# STM32G564 register map
File version: 2.0.0
CPU: CM33 r0p4, little endian, MPU, FPU, 4 interrupt priority bits
Registers are 32-bit, read-write, reset 0x0 unless marked. A register's access mark holds for its fields unless they carry their own. Offsets are from the block's base; [hi:lo] are bit positions; {n}, {i} and the like mark numbered series; 'fields as' and 'values as' point back to an identical list.

## TIM15 — TIM15 address block description
Base 0x40014000
Same registers: TIM15_S 0x50014000
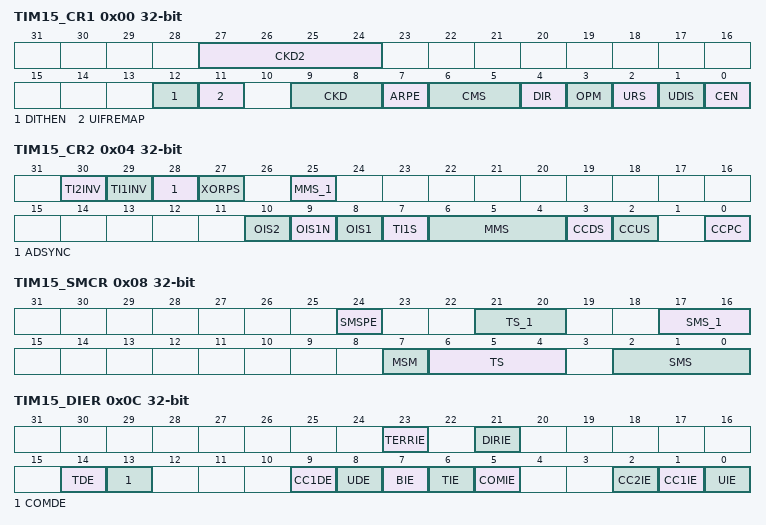
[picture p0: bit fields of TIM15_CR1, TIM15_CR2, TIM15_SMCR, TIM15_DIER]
0x00 TIM15_CR1 — TIM15 control register 1
  [27:24] CKD2 — Clock division 2
    0=No Division; 1=tless thansub>DTS2less than/sub> = 4*tless thansub>DTSless than/sub>; 2=tless thansub>DTS2less than/sub> = 16*tless thansub>DTSless than/sub>; 3=tless thansub>DTS2less than/sub> = 64*tless thansub>DTSless than/sub>; 4=tless thansub>DTS2less than/sub> = 256*tless thansub>DTSless than/sub>; 5=tless thansub>DTS2less than/sub> = 1024*tless thansub>DTSless than/sub>; 6=tless thansub>DTS2less than/sub> = 4096*tless thansub>DTSless than/sub>; 7=tless thansub>DTS2less than/sub> = 16384*tless thansub>DTSless than/sub>; 8=tless thansub>DTS2less than/sub> = 65536*tless thansub>DTSless than/sub>; 9=tless thansub>DTS2less than/sub> = 262144*tless thansub>DTSless than/sub>
  [12] DITHEN — Dithering enable
    0=Dithering disabled; 1=Dithering enabled
  [11] UIFREMAP — UIF status bit remapping
    0=No remapping. UIF status bit is not copied to TIM15_CNT register bit 31.; 1=Remapping enabled. UIF status bit is copied to TIM15_CNT register bit 31.
  [9:8] CKD — Clock division
    0=tless thansub>DTS less than/sub>= tless thansub>tim_ker_ckless than/sub>; 1=tless thansub>DTSless than/sub> = 2*tless thansub>tim_ker_ckless than/sub>; 2=tless thansub>DTSless than/sub> = 4*tless thansub>tim_ker_ckless than/sub>; 3=tless thansub>DTSless than/sub> = 8*tless thansub>tim_ker_ckless than/sub>
  [7] ARPE — Auto-reload preload enable
    0=TIM15_ARR register is not buffered; 1=TIM15_ARR register is buffered
  [6:5] CMS — Center-aligned mode selection
    0=Edge-aligned mode. The counter counts up or down depending on the direction bit (DIR).; 1=Center-aligned mode 1. The counter counts up and down alternatively. Output compare interrupt flags of channels configured in output (CCxS = 00 in TIMx_CCMRx register) are set only when the counter is counting down.; 2=Center-aligned mode 2. The counter counts up and down alternatively. Output compare interrupt flags of channels configured in output (CCxS = 00 in TIMx_CCMRx register) are set only when the counter is counting up.; 3=Center-aligned mode 3. The counter counts up and down alternatively. Output compare interrupt flags of channels configured in output (CCxS = 00 in TIMx_CCMRx register) are set both when the counter is counting up or down.
  [4] DIR — Direction
    0=Counter used as upcounter; 1=Counter used as downcounter
  [3] OPM — One-pulse mode
    0=Counter is not stopped at update event; 1=Counter stops counting at the next update event (clearing the bit CEN)
  [2] URS — Update request source
    0=Any of the following events generate an update interrupt if enabled. These events can be:; 1=Only counter overflow/underflow generates an update interrupt if enabled
  [1] UDIS — Update disable
    0=UEV enabled. The Update (UEV) event is generated by one of the following events:; 1=UEV disabled. The Update event is not generated, shadow registers keep their value (ARR, PSC, CCRx). However the counter and the prescaler are reinitialized if the UG bit is set or if a hardware reset is received from the slave mode controller.
  [0] CEN — Counter enable
    0=Counter disabled; 1=Counter enabled
0x04 TIM15_CR2 — TIM15 control register 2
  [30] TI2INV — tim_ti2 signal inversion on XOR gate input
    0=tim_ti2 non-inverted; 1=tim_ti2 inverted
  [29] TI1INV — tim_ti1 signal inversion on XOR gate input
    0=tim_ti1 non-inverted; 1=tim_ti1 inverted
  [28] ADSYNC — ADC synchronization
    0=The timer operates independently from the ADC; 1=The timer operation is synchronized with the ADC clock to provide jitter-free sampling point. This mode can be enabled only with specific ADC / timer clock relationship. Refer to Section223.4.36 for requirements.
  [27] XORPS — XOR gate position selection
    0=XOR gate placed before TI1 filter; 1=XOR gate placed after TI1 and TI2 filters
  [25] MMS_1 — MMS[3]
  [10] OIS2 — Output idle state 2 (tim_oc2 output)
    0=tim_oc2 = 0 when MOE = 0; 1=tim_oc2 = 1 when MOE = 0
  [9] OIS1N — Output Idle state 1 (tim_oc1n output)
    0=tim_oc1n = 0 after a dead-time when MOE = 0; 1=tim_oc1n = 1 after a dead-time when MOE = 0
  [8] OIS1 — Output Idle state 1 (tim_oc1 output)
    0=tim_oc1 = 0 after a dead-time when MOE = 0; 1=tim_oc1 = 1 after a dead-time when MOE = 0
  [7] TI1S — tim_ti1 selection
    0=The tim_ti1_in[15:0] multiplexer output is connected to tim_ti1 input; 1=The tim_ti1_in[15:0] and tim_ti2_in[15:0] multiplexers output are connected to the tim_ti1 input (XOR combination)
  [6:4] MMS — MMS[2:0]: Master mode selection
    0=Reset - the UG bit from the TIM15_EGR register is used as trigger output (tim_trgo). If the reset is generated by the trigger input (slave mode controller configured in reset mode) then the signal on tim_trgo is delayed compared to the actual reset.; 1=Enable - the Counter Enable signal CNT_EN is used as trigger output (tim_trgo). It is useful to start several timers at the same time or to control a window in which a slave timer is enable. The Counter Enable signal is generated by a logic AND between CEN control bit and the trigger input when configured in gated mode. When the Counter Enable signal is controlled by the trigger input, there is a delay on tim_trgo, except if the master/slave mode is selected (see the MSM bit description in TIM15_SMCR register).; 2=Update - The update event is selected as trigger output (tim_trgo). For instance a master timer can then be used as a prescaler for a slave timer.; 3=Compare Pulse - The trigger output send a positive pulse when the CC1IF flag is to be set (even if it was already high), as soon as a capture or a compare match occurred (tim_trgo); 4=Compare - tim_oc1refc signal is used as trigger output (tim_trgo); 5=Compare - tim_oc2refc signal is used as trigger output (tim_trgo)
  [3] CCDS — Capture/compare DMA selection
    0=CCx DMA request sent when CCx event occurs; 1=CCx DMA requests sent when update event occurs
  [2] CCUS — Capture/compare control update selection
    0=When capture/compare control bits are preloaded (CCPC = 1), they are updated by setting the COMG bit only; 1=When capture/compare control bits are preloaded (CCPC = 1), they are updated by setting the COMG bit or when an rising edge occurs on tim_trgi
  [0] CCPC — Capture/compare preloaded control
    0=CCxE, CCxNE and OCxM bits are not preloaded; 1=CCxE, CCxNE and OCxM bits are preloaded, after having been written, they are updated only when a commutation event (COM) occurs (COMG bit set or rising edge detected on tim_trgi, depending on the CCUS bit)
0x08 TIM15_SMCR — TIM15 slave mode control register
  [24] SMSPE — SMS preload enable
    0=SMS[4:0] bit field is not preloaded; 1=SMS[4:0] preload is enabled
  [21:20] TS_1 — TS[4:3]
  [17:16] SMS_1 — SMS[4:3]
  [7] MSM — Master/slave mode
    0=No action; 1=The effect of an event on the trigger input (tim_trgi) is delayed to allow a perfect synchronization between the current timer and its slaves (through tim_trgo). It is useful if the user wants to synchronize several timers on a single external event.
  [6:4] TS — TS[2:0]: Trigger selection
    {v}=Internal Trigger {v} (tim_itr{v}) (v=0..3); 4=tim_ti1 Edge Detector (tim_ti1f_ed); 5=Filtered Timer Input 1 (tim_ti1fp1); 6=Filtered Timer Input 2 (tim_ti2fp2)
  [2:0] SMS — SMS[2:0]: Slave mode selection
    0=Slave mode disabled - if CEN = 1 then the prescaler is clocked directly by the internal clock; 1=Quadrature encoder mode 1, x2 mode- Counter counts up/down on tim_ti1fp1 edge depending on tim_ti2fp2 level; 2=Quadrature encoder mode 2, x2 mode - Counter counts up/down on tim_ti2fp2 edge depending on tim_ti1fp1 level; 3=Quadrature encoder mode 3, x4 mode - Counter counts up/down on both tim_ti1fp1 and tim_ti2fp2 edges depending on the level of the other input; 4=Reset mode - Rising edge of the selected trigger input (tim_trgi) reinitializes the counter and generates an update of the registers; 5=Gated mode - The counter clock is enabled when the trigger input (tim_trgi) is high. The counter stops (but is not reset) as soon as the trigger becomes low. Both start and stop of the counter are controlled.; 6=Trigger mode - The counter starts at a rising edge of the trigger tim_trgi (but it is not reset). Only the start of the counter is controlled.; 7=External Clock mode 1 - Rising edges of the selected trigger (tim_trgi) clock the counter
0x0C TIM15_DIER — TIM15 DMA/interrupt enable register
  [23] TERRIE — Transition error interrupt enable
    0=Transition error interrupt disabled; 1=Transition error interrupt enabled
  [21] DIRIE — Direction change interrupt enable
    0=Direction Change interrupt disabled; 1=Direction Change interrupt enabled
  [14] TDE — Trigger DMA request enable
    0=Trigger DMA request disabled; 1=Trigger DMA request enabled
  [13] COMDE — COM DMA request enable
    0=COM DMA request disabled; 1=COM DMA request enabled
  [9] CC1DE — Capture/Compare 1 DMA request enable
    0=CC1 DMA request disabled; 1=CC1 DMA request enabled
  [8] UDE — Update DMA request enable
    0=Update DMA request disabled; 1=Update DMA request enabled
  [7] BIE — Break interrupt enable
    0=Break interrupt disabled; 1=Break interrupt enabled
  [6] TIE — Trigger interrupt enable
    0=Trigger interrupt disabled; 1=Trigger interrupt enabled
  [5] COMIE — COM interrupt enable
    0=COM interrupt disabled; 1=COM interrupt enabled
  [2] CC2IE — Capture/Compare 2 interrupt enable
    0=CC2 interrupt disabled; 1=CC2 interrupt enabled
  [1] CC1IE — Capture/Compare 1 interrupt enable
    0=CC1 interrupt disabled; 1=CC1 interrupt enabled
  [0] UIE — Update interrupt enable
    0=Update interrupt disabled; 1=Update interrupt enabled
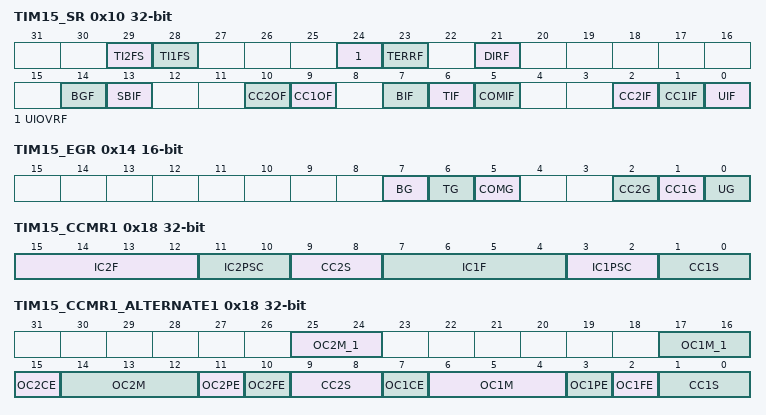
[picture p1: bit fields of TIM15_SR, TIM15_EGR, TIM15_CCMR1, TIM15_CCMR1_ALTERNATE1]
0x10 TIM15_SR — TIM15 status register
  [29] TI2FS ro — tim_ti2f status
    0=tim_ti2f signal is low; 1=tim_ti2f signal is high
  [28] TI1FS ro — tim_ti1f status
    0=tim_ti1f signal is low; 1=tim_ti1f signal is high
  [24] UIOVRF — Update Interrupt Overrun flag
    0=No Update Interrupt Overrun; 1=Update Interrupt Overrun
  [23] TERRF — Transition error interrupt flag
    0=No encoder transition error has been detected; 1=An encoder transition error has been detected
  [21] DIRF — Direction change interrupt flag
    0=No direction change; 1=Direction change
  [14] BGF — Break generation flag
    0=No break event occurred; 1=A break event was forced with the BG bit
  [13] SBIF — System break interrupt flag
    0=No break event occurred; 1=An active level has been detected on the system break input. An interrupt is generated if BIE = 1 in the TIMx_DIER register.
  [10] CC2OF — Capture/Compare 2 overcapture flag
  [9] CC1OF — Capture/Compare 1 overcapture flag
    0=No overcapture has been detected; 1=The counter value has been captured in TIM15_CCR1 register while CC1IF flag was already set
  [7] BIF — Break interrupt flag
    0=No break event occurred; 1=An active level has been detected on the break input
  [6] TIF — Trigger interrupt flag
    0=No trigger event occurred; 1=Trigger interrupt pending
  [5] COMIF — COM interrupt flag
    0=No COM event occurred; 1=COM interrupt pending
  [2] CC2IF — Capture/Compare 2 interrupt flag
  [1] CC1IF — Capture/Compare 1 interrupt flag
    0=No compare match / No input capture occurred; 1=A compare match or an input capture occurred
  [0] UIF — Update interrupt flag
    0=No update occurred; 1=Update interrupt pending. This bit is set by hardware when the registers are updated:
0x14 TIM15_EGR 16-bit — TIM15 event generation register
  [7] BG wo — Break generation
    0=No action; 1=A break event is generated. MOE bit is cleared and BIF flag is set. Related interrupt or DMA transfer can occur if enabled.
  [6] TG wo — Trigger generation
    0=No action; 1=The TIF flag is set in TIM15_SR register. Related interrupt or DMA transfer can occur if enabled
  [5] COMG — Capture/Compare control update generation
    0=No action; 1=When the CCPC bit is set, it is possible to update the CCxE, CCxNE and OCxM bits
  [2] CC2G wo — Capture/Compare 2 generation
  [1] CC1G wo — Capture/Compare 1 generation
    0=No action
  [0] UG wo — Update generation
    0=No action; 1=Reinitialize the counter and generates an update of the registers. Note that the prescaler counter is cleared too (anyway the prescaler ratio is not affected).
0x18 TIM15_CCMR1 — TIM15 capture/compare mode register 1
  [15:12] IC2F — Input capture 2 filter
  [11:10] IC2PSC — Input capture 2 prescaler
  [9:8] CC2S — Capture/Compare 2 selection
    0=CC2 channel is configured as output; 1=CC2 channel is configured as input, tim_ic2 is mapped on tim_ti2; 2=CC2 channel is configured as input, tim_ic2 is mapped on tim_ti1; 3=CC2 channel is configured as input, tim_ic2 is mapped on tim_trc. This mode is working only if an internal trigger input is selected through TS bit (TIM15_SMCR register)
  [7:4] IC1F — Input capture 1 filter
    0=No filter, sampling is done at fless thansub>DTSless than/sub>; 1=fless thansub>SAMPLINGless than/sub> = fless thansub>tim_ker_ckless than/sub>, N = 2; 2=fless thansub>SAMPLINGless than/sub> = fless thansub>tim_ker_ckless than/sub>, N = 4; 3=fless thansub>SAMPLINGless than/sub> = fless thansub>tim_ker_ckless than/sub>, N = 8; 4=fless thansub>SAMPLINGless than/sub> = fless thansub>DTSless than/sub>/2, N = 6; 5=fless thansub>SAMPLINGless than/sub> = fless thansub>DTSless than/sub>/2, N = 8; 6=fless thansub>SAMPLINGless than/sub> = fless thansub>DTSless than/sub>/4, N = 6; 7=fless thansub>SAMPLINGless than/sub> = fless thansub>DTSless than/sub>/4, N = 8; 8=fless thansub>SAMPLINGless than/sub> = fless thansub>DTSless than/sub>/8, N = 6; 9=fless thansub>SAMPLINGless than/sub> = fless thansub>DTSless than/sub>/8, N = 8; 10=fless thansub>SAMPLINGless than/sub> = fless thansub>DTSless than/sub>/16, N = 5; 11=fless thansub>SAMPLINGless than/sub> = fless thansub>DTSless than/sub>/16, N = 6; 12=fless thansub>SAMPLINGless than/sub> = fless thansub>DTSless than/sub>/16, N = 8; 13=fless thansub>SAMPLINGless than/sub> = fless thansub>DTSless than/sub>/32, N = 5; 14=fless thansub>SAMPLINGless than/sub> = fless thansub>DTSless than/sub>/32, N = 6; 15=fless thansub>SAMPLINGless than/sub> = fless thansub>DTSless than/sub>/32, N = 8
  [3:2] IC1PSC — Input capture 1 prescaler
    0=no prescaler, capture is done each time an edge is detected on the capture input; 1=capture is done once every 2 events; 2=capture is done once every 4 events; 3=capture is done once every 8 events
  [1:0] CC1S — Capture/Compare 1 selection
    0=CC1 channel is configured as output; 1=CC1 channel is configured as input, tim_ic1 is mapped on tim_ti1; 2=CC1 channel is configured as input, tim_ic1 is mapped on tim_ti2; 3=CC1 channel is configured as input, tim_ic1 is mapped on tim_trc. This mode is working only if an internal trigger input is selected through TS bit (TIM15_SMCR register)
0x18 TIM15_CCMR1_ALTERNATE1 (alternate view of TIM15_CCMR1) — TIM15 capture/compare mode register 1
  [25:24] OC2M_1 — OC2M[4:3]
  [17:16] OC1M_1 — OC1M[4:3]
  [15] OC2CE — Output compare 2 clear enable
  [14:12] OC2M — OC2M[2:0]: Output compare 2 mode
  [11] OC2PE — Output compare 2 preload enable
  [10] OC2FE — Output compare 2 fast enable
  [9:8] CC2S — Capture/Compare 2 selection
    0=CC2 channel is configured as output; 1=CC2 channel is configured as input, tim_ic2 is mapped on tim_ti2; 2=C2 channel is configured as input, tim_ic2 is mapped on tim_ti1; 3=CC2 channel is configured as input, tim_ic2 is mapped on tim_trc. This mode is working only if an internal trigger input is selected through the TS bit (TIM15_SMCR register)
  [7] OC1CE — Output compare 1 clear enable
    0=tim_oc1ref is not affected by the tim_ocref_clr_int input; 1=tim_oc1ref is cleared as soon as a High level is detected on tim_ocref_clr_int input
  [6:4] OC1M — OC1M[2:0]: Output compare 1 mode
    0=Frozen - The comparison between the output compare register TIM15_CCR1 and the counter TIM15_CNT has no effect on the outputs. This mode can be used when the timer serves as a software timebase. When the frozen mode is enabled during timer operation, the output keeps the state (active or inactive) it had before entering the frozen state.; 1=Set channel 1 to active level on match. tim_oc1ref signal is forced high when the counter TIM15_CNT matches the capture/compare register 1 (TIM15_CCR1).; 2=Set channel 1 to inactive level on match. tim_oc1ref signal is forced low when the counter TIM15_CNT matches the capture/compare register 1 (TIM15_CCR1).; 3=Toggle - tim_oc1ref toggles when TIM15_CNT = TIM15_CCR1; 4=Force inactive level - tim_oc1ref is forced low; 5=Force active level - tim_oc1ref is forced high; 6=PWM mode 1 - Channel 1 is active as long as TIM15_CNTless thanTIM15_CCR1 else inactive; 7=PWM mode 2 - Channel 1 is inactive as long as TIM15_CNTless thanTIM15_CCR1 else active
  [3] OC1PE — Output Compare 1 preload enable
    0=Preload register on TIM15_CCR1 disabled. TIM15_CCR1 can be written at anytime, the new value is taken in account immediately.; 1=Preload register on TIM15_CCR1 enabled. Read/Write operations access the preload register. TIM15_CCR1 preload value is loaded in the active register at each update event.
  [2] OC1FE — Output Compare 1 fast enable
    0=CC1 behaves normally depending on counter and CCR1 values even when the trigger is ON. The minimum delay to activate CC1 output when an edge occurs on the trigger input is 5 clock cycles.; 1=An active edge on the trigger input acts like a compare match on CC1 output. Then, tim_ocx is set to the compare level independently of the result of the comparison. Delay to sample the trigger input and to activate CC1 output is reduced to 3 clock cycles. OCFE acts only if the channel is configured in PWM1 or PWM2 mode.
  [1:0] CC1S — Capture/Compare 1 selection
    values as TIM15_CCMR1.CC1S
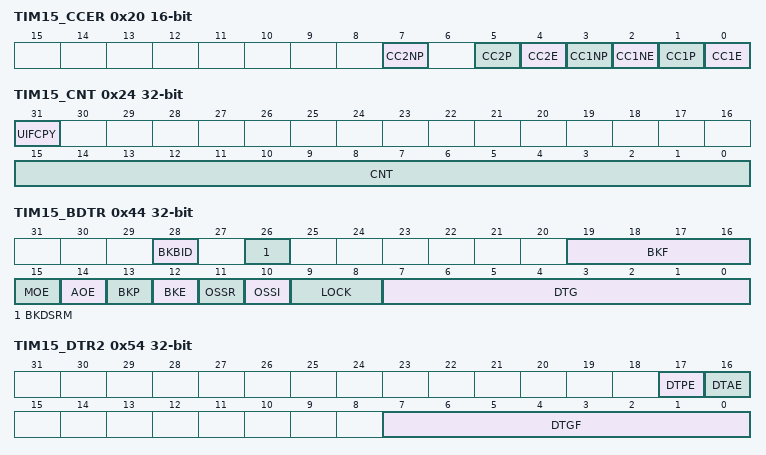
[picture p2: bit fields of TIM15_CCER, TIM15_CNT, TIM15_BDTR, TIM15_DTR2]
0x20 TIM15_CCER 16-bit — TIM15 capture/compare enable register
  [7] CC2NP — Capture/Compare 2 complementary output polarity
  [5] CC2P — Capture/Compare 2 output polarity
  [4] CC2E — Capture/Compare 2 output enable
  [3] CC1NP — Capture/Compare 1 complementary output polarity
    0=tim_oc1n active high; 1=tim_oc1n active low
  [2] CC1NE — Capture/Compare 1 complementary output enable
    0=Off - tim_oc1n is not active. tim_oc1n level is then function of MOE, OSSI, OSSR, OIS1, OIS1N and CC1E bits.; 1=On - tim_oc1n signal is output on the corresponding output pin depending on MOE, OSSI, OSSR, OIS1, OIS1N and CC1E bits
  [1] CC1P — Capture/Compare 1 output polarity
    0=OC1 active high (output mode) / Edge sensitivity selection (input mode, see below); 1=OC1 active low (output mode) / Edge sensitivity selection (input mode, see below)
  [0] CC1E — Capture/Compare 1 output enable
    0=Capture mode disabled / OC1 is not active (see below); 1=Capture mode enabled / OC1 signal is output on the corresponding output pin
0x24 TIM15_CNT — TIM15 counter
  [31] UIFCPY ro — UIF Copy
  [15:0] CNT — Counter value
0x28 TIM15_PSC 16-bit — TIM15 prescaler
  [15:0] PSC — Prescaler value
0x2C TIM15_ARR reset 0xFFFF — TIM15 autoreload register
  [19:0] ARR — Auto-reload value
0x30 TIM15_RCR 16-bit — TIM15 repetition counter register
  [7:0] REP — Repetition counter reload value
0x34 TIM15_CCR1 — TIM15 capture/compare register 1
  [19:0] CCR1 — Capture/compare 1 value
0x38 TIM15_CCR2 — TIM15 capture/compare register 2
  [19:0] CCR2 — Capture/compare 2 value
0x44 TIM15_BDTR — TIM15 break and dead-time register
  [28] BKBID — Break bidirectional
    0=Break input tim_brk in input mode; 1=Break input tim_brk in bidirectional mode
  [26] BKDSRM — Break disarm
    0=Break input tim_brk is armed; 1=Break input tim_brk is disarmed
  [19:16] BKF — Break filter
    0=No filter, tim_brk acts asynchronously; 1=fless thansub>SAMPLINGless than/sub> = fless thansub>tim_ker_ckless than/sub>, N = 2; 2=fless thansub>SAMPLINGless than/sub> = fless thansub>tim_ker_ckless than/sub>, N = 4; 3=fless thansub>SAMPLINGless than/sub> = fless thansub>tim_ker_ckless than/sub>, N = 8; 4=fless thansub>SAMPLINGless than/sub> = fless thansub>DTSless than/sub>/2, N = 6; 5=fless thansub>SAMPLINGless than/sub> = fless thansub>DTSless than/sub>/2, N = 8; 6=fless thansub>SAMPLINGless than/sub> = fless thansub>DTSless than/sub>/4, N = 6; 7=fless thansub>SAMPLINGless than/sub> = fless thansub>DTSless than/sub>/4, N = 8; 8=fless thansub>SAMPLINGless than/sub> = fless thansub>DTSless than/sub>/8, N = 6; 9=fless thansub>SAMPLINGless than/sub> = fless thansub>DTSless than/sub>/8, N = 8; 10=fless thansub>SAMPLINGless than/sub> = fless thansub>DTSless than/sub>/16, N = 5; 11=fless thansub>SAMPLINGless than/sub> = fless thansub>DTSless than/sub>/16, N = 6; 12=fless thansub>SAMPLINGless than/sub> = fless thansub>DTSless than/sub>/16, N = 8; 13=fless thansub>SAMPLINGless than/sub> = fless thansub>DTSless than/sub>/32, N = 5; 14=fless thansub>SAMPLINGless than/sub> = fless thansub>DTSless than/sub>/32, N = 6; 15=fless thansub>SAMPLINGless than/sub> = fless thansub>DTSless than/sub>/32, N = 8
  [15] MOE — Main output enable
    0=tim_ocx and tim_ocxn outputs are disabled or forced to idle state depending on the OSSI bit; 1=tim_ocx and tim_ocxn outputs are enabled if their respective enable bits are set (CCxE, CCxNE in TIM15_CCER register)
  [14] AOE — Automatic output enable
    0=MOE can be set only by software; 1=MOE can be set by software or automatically at the next update event (if the break input is not be active)
  [13] BKP — Break polarity
    0=Break input tim_brk is active low; 1=Break input tim_brk is active high
  [12] BKE — Break enable
    0=Break inputs (tim_brk and tim_sys_brk clock failure event) disabled; 1=Break inputs (tim_brk and tim_sys_brk clock failure event) enabled
  [11] OSSR — Off-state selection for Run mode
    0=When inactive, tim_ocx/tim_ocxn outputs are disabled (the timer releases the output control which is taken over by the GPIO, which forces a Hi-Z state); 1=When inactive, tim_ocx/tim_ocxn outputs are enabled with their inactive level as soon as CCxE = 1 or CCxNE = 1 (the output is still controlled by the timer)
  [10] OSSI — Off-state selection for Idle mode
    0=When inactive, tim_ocx/tim_ocxn outputs are disabled (tim_ocx/tim_ocxn enable output signal = 0); 1=When inactive, tim_ocx/tim_ocxn outputs are forced first with their idle level as soon as CCxE = 1 or CCxNE = 1. tim_ocx/tim_ocxn enable output signal = 1)
  [9:8] LOCK — Lock configuration
    0=LOCK OFF - No bit is write protected; 1=LOCK Level 1 = DTG bits in TIM15_BDTR register, OISx and OISxN bits in TIM15_CR2 register and BKBID/BKE/BKP/AOE bits in TIM15_BDTR register can no longer be written; 2=LOCK Level 2 = LOCK Level 1 + CC Polarity bits (CCxP/CCxNP bits in TIM15_CCER register, as long as the related channel is configured in output through the CCxS bits) as well as OSSR and OSSI bits can no longer be written; 3=OCK Level 3 = LOCK Level 2 + CC Control bits (OCxM and OCxPE bits in TIM15_CCMRx registers, as long as the related channel is configured in output through the CCxS bits) can no longer be written
  [7:0] DTG — Dead-time generator setup
0x54 TIM15_DTR2 — TIM15 timer deadtime register 2
  [17] DTPE — Deadtime preload enable
    0=Deadtime value is not preloaded; 1=Deadtime value preload is enabled
  [16] DTAE — Deadtime asymmetric enable
    0=Deadtime on rising and falling edges are identical, and defined with DTG[7:0] register; 1=Deadtime on rising edge is defined with DTG[7:0] register and deadtime on falling edge is defined with DTGF[7:0] bits
  [7:0] DTGF — Dead-time falling edge generator setup
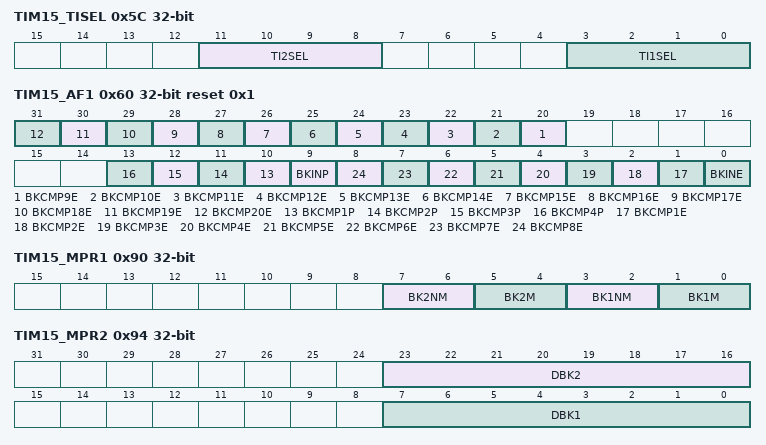
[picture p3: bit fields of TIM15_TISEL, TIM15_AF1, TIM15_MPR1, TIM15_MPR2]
0x5C TIM15_TISEL — TIM15 input selection register
  [11:8] TI2SEL — selects tim_ti2_in[15:0] input
    0=TIM15_CH2 input (tim_ti2_in0); 1=tim_ti2_in1; 15=tim_ti2_in15
  [3:0] TI1SEL — selects tim_ti1_in[15:0] input
    0=TIM15_CH1 input (tim_ti1_in0); 1=tim_ti1_in1; 15=tim_ti1_in15
0x60 TIM15_AF1 reset 0x1 — TIM15 alternate function register 1
  [n+11] BKCMP{n}E (n=9..20) — tim_brk_cmp{n} enable
    0=tim_brk_cmp{n} input disabled; 1=tim_brk_cmp{n} input enabled
  [n+9] BKCMP{n}P (n=1..4) — tim_brk_cmp{n} input polarity
    0=tim_brk_cmp{n} input is active high; 1=tim_brk_cmp{n} input is active low
  [9] BKINP — TIMx_BKIN input polarity
    0=TIMx_BKIN input is active high; 1=TIMx_BKIN input is active low
  [n] BKCMP{n}E (n=1..8) — tim_brk_cmp{n} enable
    values as BKCMP9E
  [0] BKINE — TIMx_BKIN input enable
    0=TIMx_BKIN input disabled; 1=TIMx_BKIN input enabled
0x64 TIM15_AF2 — TIM15 alternate function register 2
  [19:16] OCRSEL — ocref_clr source selection
    0=tim_ocref_clr0; 1=tim_ocref_clr1; 15=tim_ocref_clr15
0x90 TIM15_MPR1 — TIM15 multilevel protection register 1
  [all] fields
    0=Immediate break; 1=Delayed 1 break; 2=Delayed 2 break
  [7:6] BK2NM — Break mode for tim_oc2n output
  [5:4] BK2M — Break mode for tim_oc2 output
  [3:2] BK1NM — Break mode for tim_oc1n output
  [1:0] BK1M — Break mode for tim_oc1 output
0x94 TIM15_MPR2 — TIM15 multilevel protection register 2
  [23:16] DBK2 — Delayed 2 Break duration
  [7:0] DBK1 — Delayed 1 Break duration
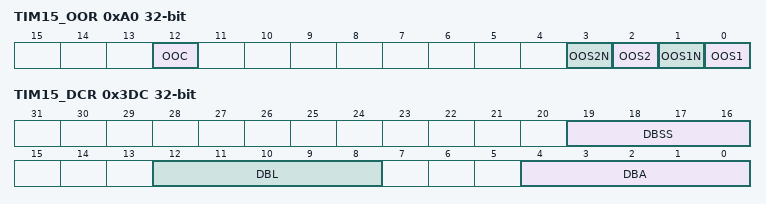
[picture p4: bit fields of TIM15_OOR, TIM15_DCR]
0xA0 TIM15_OOR — TIM15 output override register
  [12] OOC — Output override control
    0=tim_ocx and tim_ocxn outputs are in the default idle state; 1=tim_ocx and tim_ocxn outputs are forced in an idle state defined with OOSx/OOSxN bits
  [3] OOS2N — Output override state for output tim_oc2n
    0=tim_oc2n = 0; 1=tim_oc2n = 1
  [2] OOS2 — Output override state for output tim_oc2
    0=tim_oc2 = 0; 1=tim_oc2 = 1
  [1] OOS1N — Output override state for output tim_oc1n
    0=tim_oc1n = 0; 1=tim_oc1n = 1
  [0] OOS1 — Output override state for output tim_oc1
    0=tim_oc1 = 0; 1=tim_oc1 = 1
0x3DC TIM15_DCR — TIM15 DMA control register
  [19:16] DBSS — DMA burst source selection
    1=Update; 2=CC1; 6=COM; 7=Trigger
  [12:8] DBL — DMA burst length
    0=1 transfer; 1=2 transfers; 2=3 transfers; 31=32 transfers
  [4:0] DBA — DMA base address
    0=TIM15_CR1; 1=TIM15_CR2; 2=TIM15_SMCR
0x3E0 TIM15_DMAR — TIM15 DMA address for full transfer
  [31:0] DMAB — DMA register for burst accesses
